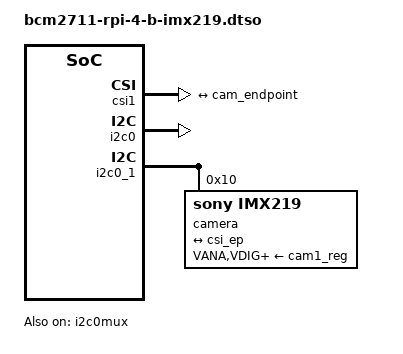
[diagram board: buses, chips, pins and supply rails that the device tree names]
// SPDX-License-Identifier: GPL-2.0-only
// Definitions for IMX219 camera module on VC I2C bus

/dts-v1/;
/plugin/;

&{/} {
	cam1_clk: cam1_clk {
		compatible = "fixed-clock";
		#clock-cells = <0>;
		clock-frequency = <24000000>;
	};
};

&csi1 {
	status = "okay";

	port {
		csi_ep: endpoint {
			remote-endpoint = <&cam_endpoint>;
			clock-lanes = <0>;
			data-lanes = <1 2>;
			clock-noncontinuous;
		};
	};
};

&i2c0 {
	status = "okay";
};

&i2c0_1 {
	#address-cells = <1>;
	#size-cells = <0>;
	status = "okay";

	camera@10 {
		compatible = "sony,imx219";
		reg = <0x10>;

		clocks = <&cam1_clk>;
		clock-names = "xclk";

		VANA-supply = <&cam1_reg>;	/* 2.8v */
		VDIG-supply = <&cam1_reg>;	/* 1.8v */
		VDDL-supply = <&cam1_reg>;	/* 1.2v */

		rotation = <180>;
		orientation = <2>;

		port {
			cam_endpoint: endpoint {
				remote-endpoint = <&csi_ep>;
				clock-lanes = <0>;
				data-lanes = <1 2>;
				clock-noncontinuous;
				link-frequencies = /bits/ 64 <456000000>;
			};
		};
	};
};

&i2c0mux {
	status = "okay";
};
